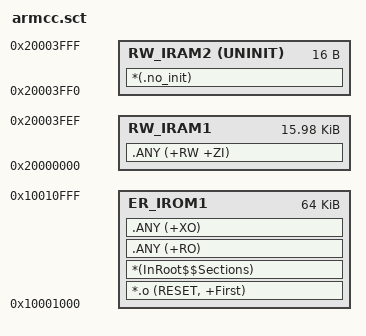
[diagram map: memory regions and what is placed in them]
; *************************************************************
; *** Scatter-Loading Description File generated by uVision ***
; *************************************************************

LR_IROM1 0x10001000 0x00010000  {    ; load region size_region
  ER_IROM1 0x10001000 0x00010000  {  ; load address = execution address
   *.o (RESET, +First)
   *(InRoot$$Sections)
   .ANY (+RO)
   .ANY (+XO)
  }

  RW_IRAM1 0x20000000 0x00003FF0  {  ; RW data
   .ANY (+RW +ZI)
  }
  
  RW_IRAM2 0x20003FF0 UNINIT 0x0000010  { ;no init section
        *(.no_init)
   }  
}

